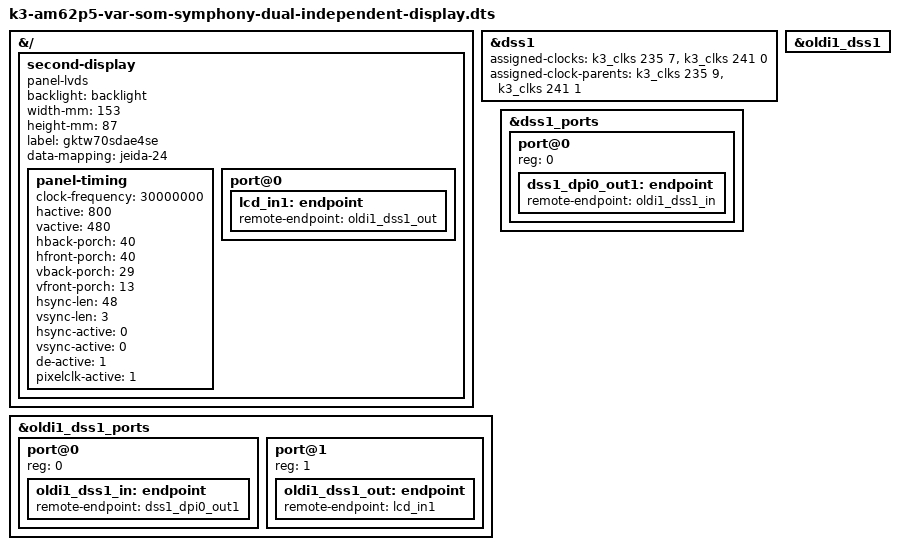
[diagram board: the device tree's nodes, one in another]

// Take the k3-am62p5-var-som-symphony as basis
#include "k3-am62p5-var-som-symphony.dts"

&{/} {
	second-display {
		compatible = "panel-lvds";
		backlight = <&backlight>;
		width-mm = <153>;
		height-mm = <87>;
		label = "gktw70sdae4se";
		data-mapping = "jeida-24";
		status = "okay";

		panel-timing {
			clock-frequency = <30000000>;
			hactive = <800>;
			vactive = <480>;
			hback-porch = <40>;
			hfront-porch = <40>;
			vback-porch = <29>;
			vfront-porch = <13>;
			hsync-len = <48>;
			vsync-len = <3>;
			hsync-active = <0>;
			vsync-active = <0>;
			de-active = <1>;

			/* unlike most panels this panel expects pixelclk-active = <1> */
			pixelclk-active = <1>;
		};

		port@0 {
			lcd_in1: endpoint {
				remote-endpoint = <&oldi1_dss1_out>;
			};
		};
	};
};

&dss1 {
	status = "okay";
	assigned-clocks = <&k3_clks 235 7>,
			  <&k3_clks 241 0>;
	assigned-clock-parents = <&k3_clks 235 9>, /* OLDI TX1 driven by PLL18 and DSS1 VP0 */
				 <&k3_clks 241 1>; /* PLL18 for DSS1 VP0 */
};

&oldi1_dss1 {
	status = "okay";
};

&oldi1_dss1_ports {
	#address-cells = <1>;
	#size-cells = <0>;

	port@0 {
		reg = <0>;
		oldi1_dss1_in: endpoint {
			remote-endpoint = <&dss1_dpi0_out1>;
		};
	};

	port@1 {
		reg = <1>;
		oldi1_dss1_out: endpoint {
			remote-endpoint = <&lcd_in1>;
		};
	};
};

&dss1_ports {
	#address-cells = <1>;
	#size-cells = <0>;
	/* DSS1 VP1: Output to OLDI1 */
	port@0 {
		reg = <0>;
		dss1_dpi0_out1: endpoint {
			remote-endpoint = <&oldi1_dss1_in>;
		};
	};
};
